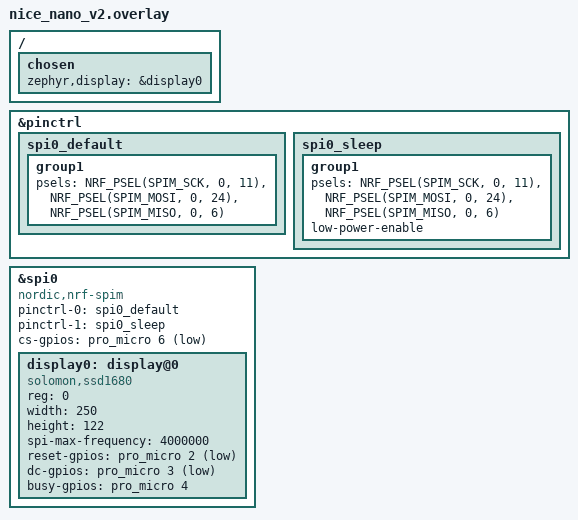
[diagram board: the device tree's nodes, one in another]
&pinctrl{

    spi0_default: spi0_default {
        group1 {
            /* main role: configure P0.01 as SPI clock, P0.02 as SPI MOSI, P0.03 as SPI MISO */
            psels = <NRF_PSEL(SPIM_SCK, 0, 11)>,
                    <NRF_PSEL(SPIM_MOSI, 0, 24)>,
                    <NRF_PSEL(SPIM_MISO, 0, 6)>;

        };
    };

    spi0_sleep: spi0_sleep {
        group1 {
            /* main role: configure P0.01 as SPI clock, P0.02 as SPI MOSI, P0.03 as SPI MISO */
            psels = <NRF_PSEL(SPIM_SCK, 0, 11)>,
                    <NRF_PSEL(SPIM_MOSI, 0, 24)>,
                    <NRF_PSEL(SPIM_MISO, 0, 6)>;
            low-power-enable;

        };
    };
    
};

&spi0 {
    status = "okay";
    compatible = "nordic,nrf-spim";
    pinctrl-0 = <&spi0_default>;
    pinctrl-1 = <&spi0_sleep>;
    pinctrl-names = "default", "sleep";
    cs-gpios = <&pro_micro 6 GPIO_ACTIVE_LOW>;

    display0: display@0 {
        compatible = "solomon,ssd1680";
        status = "okay";
        reg = <0>;
        width = <250>;
        height = <122>;
        spi-max-frequency = <4000000>;
        reset-gpios = <&pro_micro 2 GPIO_ACTIVE_LOW>;
        dc-gpios = <&pro_micro 3 GPIO_ACTIVE_LOW>;
        busy-gpios = <&pro_micro 4 GPIO_ACTIVE_HIGH>;
            
    };
};

/ {
    chosen {
        zephyr,display = &display0;
    };
};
